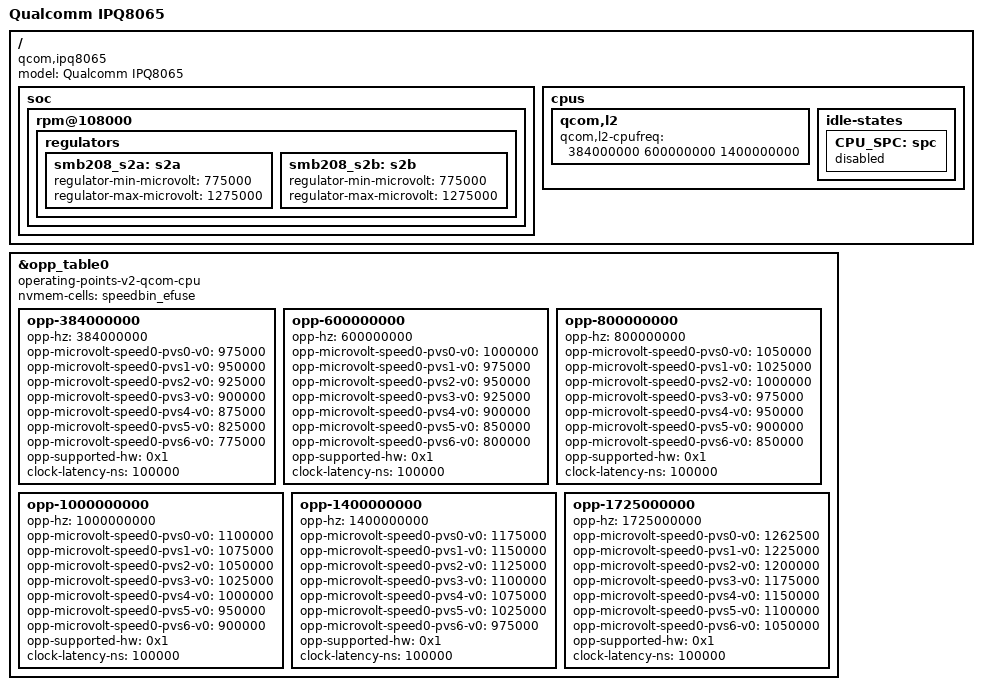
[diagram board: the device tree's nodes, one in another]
#include "qcom-ipq8064-v2.0.dtsi"

/ {
	model = "Qualcomm IPQ8065";
	compatible = "qcom,ipq8065", "qcom,ipq8064";

	soc: soc {

		rpm@108000 {

			regulators {

				smb208_s2a: s2a {
					regulator-min-microvolt = <775000>;
					regulator-max-microvolt = <1275000>;
				};

				smb208_s2b: s2b {
					regulator-min-microvolt = <775000>;
					regulator-max-microvolt = <1275000>;
				};
			};
		};
	};
	
	cpus {
		qcom,l2 {
			qcom,l2-cpufreq = <384000000 600000000 1400000000>;
		};

		idle-states {
			CPU_SPC: spc {
				status = "disabled";
			};
		};
	};
};

&opp_table0 {
	compatible = "operating-points-v2-qcom-cpu";
	nvmem-cells = <&speedbin_efuse>;

	/* 
	 * On ipq8065 1.2 ghz freq is not present
	 * Remove it to make cpufreq work and not
	 * complain for missing definition
	 */

	/delete-node/opp-1200000000;

	opp-384000000 {
		opp-hz = /bits/ 64 <384000000>;
		opp-microvolt-speed0-pvs0-v0 = <975000>;
		opp-microvolt-speed0-pvs1-v0 = <950000>;
		opp-microvolt-speed0-pvs2-v0 = <925000>;
		opp-microvolt-speed0-pvs3-v0 = <900000>;
		opp-microvolt-speed0-pvs4-v0 = <875000>;
		opp-microvolt-speed0-pvs5-v0 = <825000>;
		opp-microvolt-speed0-pvs6-v0 = <775000>;
		opp-supported-hw = <0x1>;
		clock-latency-ns = <100000>;
	};

	opp-600000000 {
		opp-hz = /bits/ 64 <600000000>;
		opp-microvolt-speed0-pvs0-v0 = <1000000>;
		opp-microvolt-speed0-pvs1-v0 = <975000>;
		opp-microvolt-speed0-pvs2-v0 = <950000>;
		opp-microvolt-speed0-pvs3-v0 = <925000>;
		opp-microvolt-speed0-pvs4-v0 = <900000>;
		opp-microvolt-speed0-pvs5-v0 = <850000>;
		opp-microvolt-speed0-pvs6-v0 = <800000>;
		opp-supported-hw = <0x1>;
		clock-latency-ns = <100000>;
	};

	opp-800000000 {
		opp-hz = /bits/ 64 <800000000>;
		opp-microvolt-speed0-pvs0-v0 = <1050000>;
		opp-microvolt-speed0-pvs1-v0 = <1025000>;
		opp-microvolt-speed0-pvs2-v0 = <1000000>;
		opp-microvolt-speed0-pvs3-v0 = <975000>;
		opp-microvolt-speed0-pvs4-v0 = <950000>;
		opp-microvolt-speed0-pvs5-v0 = <900000>;
		opp-microvolt-speed0-pvs6-v0 = <850000>;
		opp-supported-hw = <0x1>;
		clock-latency-ns = <100000>;
	};

	opp-1000000000 {
		opp-hz = /bits/ 64 <1000000000>;
		opp-microvolt-speed0-pvs0-v0 = <1100000>;
		opp-microvolt-speed0-pvs1-v0 = <1075000>;
		opp-microvolt-speed0-pvs2-v0 = <1050000>;
		opp-microvolt-speed0-pvs3-v0 = <1025000>;
		opp-microvolt-speed0-pvs4-v0 = <1000000>;
		opp-microvolt-speed0-pvs5-v0 = <950000>;
		opp-microvolt-speed0-pvs6-v0 = <900000>;
		opp-supported-hw = <0x1>;
		clock-latency-ns = <100000>;
	};

	opp-1400000000 {
		opp-hz = /bits/ 64 <1400000000>;
		opp-microvolt-speed0-pvs0-v0 = <1175000>;
		opp-microvolt-speed0-pvs1-v0 = <1150000>;
		opp-microvolt-speed0-pvs2-v0 = <1125000>;
		opp-microvolt-speed0-pvs3-v0 = <1100000>;
		opp-microvolt-speed0-pvs4-v0 = <1075000>;
		opp-microvolt-speed0-pvs5-v0 = <1025000>;
		opp-microvolt-speed0-pvs6-v0 = <975000>;
		opp-supported-hw = <0x1>;
		clock-latency-ns = <100000>;
	};

	opp-1725000000 {
		opp-hz = /bits/ 64 <1725000000>;
		opp-microvolt-speed0-pvs0-v0 = <1262500>;
		opp-microvolt-speed0-pvs1-v0 = <1225000>;
		opp-microvolt-speed0-pvs2-v0 = <1200000>;
		opp-microvolt-speed0-pvs3-v0 = <1175000>;
		opp-microvolt-speed0-pvs4-v0 = <1150000>;
		opp-microvolt-speed0-pvs5-v0 = <1100000>;
		opp-microvolt-speed0-pvs6-v0 = <1050000>;
		opp-supported-hw = <0x1>;
		clock-latency-ns = <100000>;
	};
};
